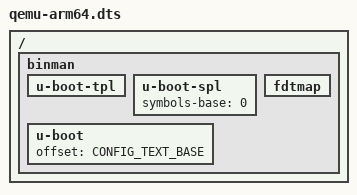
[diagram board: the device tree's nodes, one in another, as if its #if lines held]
// SPDX-License-Identifier: GPL-2.0+ OR MIT
/*
 * Empty device tree for qemu_arm64

 * Copyright 2021 Google LLC
 */

/dts-v1/;

/ {
#ifdef CONFIG_BINMAN
	binman {
		u-boot-tpl {
		};

		u-boot-spl {
			symbols-base = <0>;
		};

		u-boot {
			offset = <CONFIG_TEXT_BASE>;
		};

		fdtmap {
		};
	};
#endif
};
